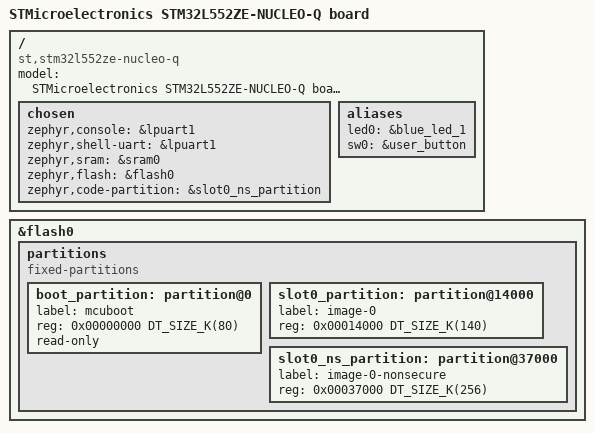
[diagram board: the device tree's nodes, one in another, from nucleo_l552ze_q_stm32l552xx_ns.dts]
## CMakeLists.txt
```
cmake_minimum_required(VERSION 3.20.0)

# Ensure USART2 (VCP) overlay is applied (force cache for sysbuild)
set(DTC_OVERLAY_FILE ${CMAKE_CURRENT_LIST_DIR}/boards/nucleo_l552ze_q.overlay CACHE STRING "" FORCE)

find_package(Zephyr REQUIRED HINTS $ENV{ZEPHYR_BASE})

project(tensorflow_hello_world)

# ============================================================
# TF-M CONFIG
# ============================================================
if(TARGET tfm)
  get_target_property(TFM_BINARY_DIR tfm TFM_BINARY_DIR)

  configure_file(
    ${CMAKE_CURRENT_LIST_DIR}/dummy_partition/tfm_manifest_list.yaml.in
    ${CMAKE_CURRENT_BINARY_DIR}/dummy_partition/tfm_manifest_list.yaml
  )

  set_property(TARGET zephyr_property_target
    APPEND PROPERTY TFM_CMAKE_OPTIONS
    -DTFM_EXTRA_MANIFEST_LIST_FILES=${CMAKE_CURRENT_BINARY_DIR}/dummy_partition/tfm_manifest_list.yaml
    -DTFM_EXTRA_PARTITION_PATHS=${CMAKE_CURRENT_LIST_DIR}/dummy_partition
  )
endif()

# ============================================================
# C++ static init fix (important for Cortex-M)
# ============================================================
set(NO_THREADSAFE_STATICS $<TARGET_PROPERTY:compiler-cpp,no_threadsafe_statics>)
zephyr_compile_options($<$<COMPILE_LANGUAGE:CXX>:${NO_THREADSAFE_STATICS}>)

# ============================================================
# Application sources
# ============================================================
target_sources(app PRIVATE
    src/main.cpp
    src/create_enclave.cpp
    src/split_inference.cpp
    src/test_images.c
    src/benchmark.cpp
    src/secure_benchmark_ns.cpp
    src/inference_protocol.cpp
    src/uart_protocol.cpp
    split_inference/late/L_nn_wt_encrypted_data.c
    src/run_enclave.cpp
)

target_link_options(app PRIVATE
    -Wl,--undefined=ns_run_enclave
)

zephyr_linker_sources(SECTIONS ${CMAKE_CURRENT_SOURCE_DIR}/src/model_ro.ld)
#zephyr_linker_sources(SECTIONS linker.ld)

# ============================================================
# Include directories (APP ONLY)
# ============================================================
target_include_directories(app PRIVATE
    ${TFM_BINARY_DIR}/api_ns/interface/include

    # TFLite Micro
    ${ZEPHYR_BASE}/../optional/modules/lib/tflite-micro
    ${ZEPHYR_BASE}/../optional/modules/lib/tflite-micro/tensorflow
    ${ZEPHYR_BASE}/../optional/modules/lib/tflite-micro/tensorflow/lite
    ${ZEPHYR_BASE}/../optional/modules/lib/tflite-micro/tensorflow/lite/micro
    ${ZEPHYR_BASE}/../optional/modules/lib/tflite-micro/tensorflow/lite/kernels

    # SecureQNN / generated headers
    ${CMAKE_CURRENT_LIST_DIR}/src
    #${CMAKE_CURRENT_LIST_DIR}/src/ns
    #${CMAKE_CURRENT_LIST_DIR}/src/s
)

# ============================================================
# CMSIS-NN (Zephyr library)
# ============================================================
add_subdirectory(src/CMSIS_NN)

# ============================================================
# Compile definitions
# ============================================================
target_compile_definitions(app PRIVATE
    TFM_PARTITION_DUMMY_PARTITION
    
)

# ================= CMSIS-NN =================
set(CMSIS_NN_PATH ${CMAKE_CURRENT_SOURCE_DIR}/src/CMSIS_NN)

zephyr_include_directories(
    ${CMSIS_NN_PATH}/Include
)

file(GLOB_RECURSE CMSIS_NN_SOURCES
    ${CMSIS_NN_PATH}/Source/*.c
)

target_sources(app PRIVATE ${CMSIS_NN_SOURCES})
```

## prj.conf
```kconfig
# Copyright 2019 The TensorFlow Authors. All Rights Reserved.
#
# Licensed under the Apache License, Version 2.0 (the "License");
# you may not use this file except in compliance with the License.
# You may obtain a copy of the License at
#
#    http://www.apache.org/licenses/LICENSE-2.0
#
# Unless required by applicable law or agreed to in writing, software
# distributed under the License is distributed on an "AS IS" BASIS,
# WITHOUT WARRANTIES OR CONDITIONS OF ANY KIND, either express or implied.
# See the License for the specific language governing permissions and
# limitations under the License.
# ==============================================================================s
CONFIG_CPP=y
CONFIG_STD_CPP17=y
CONFIG_TENSORFLOW_LITE_MICRO=y
CONFIG_MAIN_STACK_SIZE=3072
CONFIG_REQUIRES_FLOAT_PRINTF=n
#CONFIG_HEAP_MEM_POOL_SIZE=65536

CONFIG_BUILD_WITH_TFM=y
CONFIG_TFM_PROFILE_TYPE_NOT_SET=y
CONFIG_TFM_CONNECTION_BASED_SERVICE_API=y
CONFIG_TFM_PARTITION_CRYPTO=y
CONFIG_TFM_IPC=y
CONFIG_MBEDTLS_PSA_CRYPTO_C=y

# ============================================================
# STM32L5 Hardware Crypto Acceleration
# ============================================================
# HW crypto is controlled by TF-M/platform defaults in this workspace.
# Keep only supported symbols here to avoid Kconfig aborts.
CONFIG_MBEDTLS_DEBUG=y

# CMSIS
CONFIG_CMSIS_NN=y

# Performance monitoring (for benchmarking)
CONFIG_THREAD_RUNTIME_STATS=y
CONFIG_SYS_HEAP_RUNTIME_STATS=y
# CONFIG_SPEED_OPTIMIZATIONS=y  # disabled: caused TF-M build to overflow FLASH


# Silence console/log output to avoid UART protocol interference
CONFIG_LOG=n
CONFIG_PRINTK=n
CONFIG_CONSOLE=n
CONFIG_UART_CONSOLE=n
CONFIG_STDOUT_CONSOLE=n
CONFIG_BOOT_BANNER=n
CONFIG_TFM_LOG_LEVEL_SILENCE=y
CONFIG_TFM_SPM_LOG_LEVEL_SILENCE=y
CONFIG_TFM_PARTITION_LOG_LEVEL_SILENCE=y
CONFIG_TFM_BL2_LOG_LEVEL_OFF=y
CONFIG_TFM_EXCEPTION_INFO_DUMP=n



#CONFIG_TFM_PARTITION_INTERNAL_TRUSTED_STORAGE=n
CONFIG_TFM_PARTITION_INITIAL_ATTESTATION=n
#CONFIG_TFM_PARTITION_PLATFORM=n
CONFIG_TFM_PARTITION_PROTECTED_STORAGE=n
CONFIG_TFM_PARTITION_FIRMWARE_UPDATE=n


#CONFIG_USERSPACE=y
#CONFIG_THREAD_STACK_INFO=y

CONFIG_SERIAL=y
CONFIG_UART_INTERRUPT_DRIVEN=y
CONFIG_GPIO=y
```

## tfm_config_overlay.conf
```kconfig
/* TF-M Crypto acceleration */
TFM_CRYPTO_ASYM_HW_ACCELERATOR=y
TFM_CRYPTO_HW_ACCELERATOR=y
CRYPTO_ENGINE_BACKEND_STM32_PKA=y
```

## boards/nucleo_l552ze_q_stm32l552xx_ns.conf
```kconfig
CONFIG_FLASH_LOAD_OFFSET=0x41000
CONFIG_FLASH_LOAD_SIZE=0x48000
```

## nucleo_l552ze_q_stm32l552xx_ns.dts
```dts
/*
 * Copyright (c) 2020 STMicroelectronics
 *
 * SPDX-License-Identifier: Apache-2.0
 */

/dts-v1/;
#include "nucleo_l552ze_q-common.dtsi"

/ {
	model = "STMicroelectronics STM32L552ZE-NUCLEO-Q board";
	compatible = "st,stm32l552ze-nucleo-q";

	#address-cells = <1>;
	#size-cells = <1>;

	chosen {
		zephyr,console = &lpuart1;
		zephyr,shell-uart = &lpuart1;
		zephyr,sram = &sram0;
		zephyr,flash = &flash0;
		zephyr,code-partition = &slot0_ns_partition;
	};

	aliases {
		led0 = &blue_led_1;
		sw0 = &user_button;
	};
};

&flash0 {

	partitions {
		compatible = "fixed-partitions";
		#address-cells = <1>;
		#size-cells = <1>;

		/*
		 * Following flash partition is compatible with requirements
		 * given in TFM configuration given for current board:
		 * multiple image boot, no tests.
		 * It might require adjustment depending on evolutions on TFM.
		 */

		boot_partition: partition@0 {
			label = "mcuboot";
			reg = <0x00000000 DT_SIZE_K(80)>;
			read-only;
		};
		/* Secure image primary slot */
		slot0_partition: partition@14000 {
			label = "image-0";
			//reg = <0x00014000 DT_SIZE_K(180)>;
			reg = <0x00014000 DT_SIZE_K(140)>; // 0x23000
		};
		/* Non-secure image primary slot */
		//slot0_ns_partition: partition@41000 { //180KB prev
		slot0_ns_partition: partition@37000 {
			label = "image-0-nonsecure";
			reg = <0x00037000 DT_SIZE_K(256)>;
			//reg = <0x00037000 DT_SIZE_K(76)>; // 0x13000
			// reg = <0x00041000 DT_SIZE_K(36)>; // 36864 = 0x9000
		}; 
		/* Secure image secondary slot */
		// slot1_partition: partition@4a000 { // prev
		/*slot1_partition: partition@4a000 {
			label = "image-1";
			//reg = <0x0004a000 DT_SIZE_K(180)>; // 184320 = 0x2d000
			reg = <0x0004a000 DT_SIZE_K(4)>;
			//reg = <0x0004a000 DT_SIZE_K(140)>;
		};*/
		/* Non-secure image secondary slot */
		// slot1_ns_partition: partition@77000 { // prev
		/*slot1_ns_partition: partition@4b000 {
		//slot1_ns_partition: partition@6d000 {
			label = "image-1-nonsecure";
			// reg = <0x00077000 DT_SIZE_K(36)>; // prev
			reg = <0x0004b000 DT_SIZE_K(4)>;
			//reg = <0x0006d000 DT_SIZE_K(76)>;
		};*/
		/* Applicative Non Volatile Storage */
		/* Not available in this config, use secure storage */
	};
};
```

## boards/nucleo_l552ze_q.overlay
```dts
/ {
    chosen {
        zephyr,console = &lpuart1;
        zephyr,shell-uart = &lpuart1;
    };
};
```

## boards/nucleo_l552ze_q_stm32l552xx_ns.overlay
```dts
/ {
    chosen {
        zephyr,console = &usart2;
        zephyr,shell-uart = &usart2;
    };
};

&usart2 {
    status = "okay";
    current-speed = <115200>;
    pinctrl-0 = <&usart2_tx_pa2 &usart2_rx_pa3>;
    pinctrl-names = "default";
};
```

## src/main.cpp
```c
#include <zephyr/kernel.h>
#include <zephyr/sys/printk.h>
#include <zephyr/device.h>
#include <zephyr/drivers/uart.h>
// #include "inference.h"  // Legacy full-model path (not used)
#include "run_enclave.h"
#include "create_enclave.h"
#include "split_inference.h"
#include "benchmark.h"
#include "secure_benchmark_ns.h"
#include "uart_protocol.h"

/* Configuration: Set to 1 for simple UART test, 0 for normal flow */
#define SIMPLE_UART_MODE 0

/* Configuration: Set to 1 for Mac interactive mode, 0 for auto test */
#define MAC_INTERACTIVE_MODE 1


/* Linker symbols pour calculs mémoire */
extern char __bss_start[];
extern char __bss_end[];
extern char __data_start[];
extern char __data_end[];

static void print_memory_stats(void)
{
    size_t bss_size = (size_t)(__bss_end - __bss_start);
    size_t data_size = (size_t)(__data_end - __data_start);

    printk("\n======= NS MEMORY STATS =======\n");
    printk("  BSS size:   %zu bytes\n", bss_size);
    printk("  DATA size:  %zu bytes\n", data_size);
    printk("  Stack ptr:  %p\n", (void*)&bss_size);
    printk("===============================\n\n");
}

/*
 * Override Zephyr's fatal error handler to print a diagnostic message
 * when the SAU isolation test triggers a HardFault (NS->Secure access).
 * After printing, the system halts (or reboots) as usual.
 */
extern "C" void k_sys_fatal_error_handler(unsigned int reason,
                                          const struct arch_esf *esf)
{
    (void)esf;
    printk("\n[SAU TEST] FATAL ERROR: HardFault (reason=%u)\n", reason);
    printk("[SAU TEST] SAU isolation VERIFIED: NS access to Secure enclave ");
    printk("window triggers HardFault as expected.\n");
    printk("[SAU TEST] ========================\n\n");
    k_fatal_halt(reason);
}

int main(void)
{
#if SIMPLE_UART_MODE
    const struct device *uart = DEVICE_DT_GET(DT_NODELABEL(lpuart1));
    if (!device_is_ready(uart)) {
        while (1) {
            k_sleep(K_FOREVER);
        }
    }

    // Simple test: Mac sends 0x01, device responds 0x02
    while (1) {
        uint8_t byte;
        if (uart_poll_in(uart, &byte) == 0) {
            if (byte == 0x01) {
                uart_poll_out(uart, 0x02);
            }
        }
        k_sleep(K_MSEC(1));
    }
#endif

    // All console output disabled to avoid interfering with binary UART protocol
    // (CONFIG_PRINTK=n in prj.conf disables printk at compile time)

    /* Initialize benchmark system */
    benchmark_init();

    // print_memory_stats();

#if MAC_INTERACTIVE_MODE
    /* MAC INTERACTIVE MODE: Device waits for commands from Mac */
    /* All console output disabled to avoid interfering with binary protocol */

    /* Initialize UART protocol */
    while (uart_protocol_init() != 0) {
        k_sleep(K_MSEC(100));
    }

    /* Main loop: process incoming commands - no console output to avoid protocol interference */
    while (1) {
        uart_protocol_process();
        k_yield();
    }

#else
    /* AUTO TEST MODE: Run automated tests */
    printk("\n[MAIN] AUTO MODE\n");
    /* Single inference in enclave */
    printk("\n[MAIN] Running single inference in enclave...\n");
    run_enclave();
    printk("[MAIN] ✓ Inference complete\n\n");

    print_memory_stats();

    /* Update final memory metrics */
    benchmark_get_heap_usage(&g_benchmark_metrics.heap_used_bytes,
                            &g_benchmark_metrics.heap_free_bytes,
                            NULL);
    g_benchmark_metrics.stack_used_bytes = benchmark_get_stack_usage();

    /* Get RAM and Flash usage */
    benchmark_get_memory_usage(&g_benchmark_metrics.ram_used_bytes,
                              &g_benchmark_metrics.ram_total_bytes,
                              &g_benchmark_metrics.flash_used_bytes,
                              &g_benchmark_metrics.flash_total_bytes);

    printk("\n========================================\n");
    printk("=== All operations completed ===\n");
    printk("========================================\n\n");

    /* Print comprehensive benchmark report */
    benchmark_print_report(&g_benchmark_metrics);

    /* Retrieve and print Secure partition benchmark */
    secure_benchmark_metrics_ns_t secure_metrics;
    if (get_secure_benchmark_metrics(&secure_metrics) == 0) {
        print_secure_benchmark_report(&secure_metrics);
    } else {
        printk("[NS] Warning: Failed to retrieve Secure benchmark metrics\n");
    }

    while (1) {
        k_sleep(K_FOREVER);
    }
#endif

    return 0;
}
```

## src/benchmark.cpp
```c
#include "benchmark.h"
#include <zephyr/kernel.h>
#include <zephyr/sys/printk.h>
#include <string.h>

// ============================================================================
// Cycle Counter - Using Zephyr's sys_clock_elapsed() instead of DWT
// (DWT is not accessible from Non-Secure world in TrustZone-M)
// ============================================================================

// System clock (STM32L552 default)
#ifndef CONFIG_SYS_CLOCK_HW_CYCLES_PER_SEC
#define CPU_FREQ_HZ 110000000  // 110 MHz default for STM32L552
#else
#define CPU_FREQ_HZ CONFIG_SYS_CLOCK_HW_CYCLES_PER_SEC
#endif

// Global metrics storage
benchmark_metrics_t g_benchmark_metrics;

// Reference point for cycle counting
static uint32_t benchmark_start_cycles = 0;

static uint32_t safe_avg_u64(uint64_t sum, uint32_t count)
{
    if (count == 0U) {
        return 0U;
    }
    return (uint32_t)(sum / count);
}

// ============================================================================
// Initialization
// ============================================================================

void benchmark_init(void)
{
    // Initialize with current kernel cycle count
    benchmark_start_cycles = k_cycle_get_32();
    
    // Reset metrics
    benchmark_reset_metrics();
    
    printk("[BENCHMARK] Initialized - CPU freq: %u MHz\n", CPU_FREQ_HZ / 1000000);
}

// ============================================================================
// Cycle Counter Implementation
// Using Zephyr's k_cycle_get_32() for TrustZone-M safe access
// ============================================================================

uint32_t benchmark_get_cycles(void)
{
    // Get current cycle count and calculate elapsed
    uint32_t current_cycles = k_cycle_get_32();
    uint32_t elapsed_cycles = current_cycles - benchmark_start_cycles;
    
    return elapsed_cycles;
}

uint32_t benchmark_cycles_to_us(uint32_t cycles)
{
    // Convert cycles to microseconds
    // us = cycles / (freq_hz / 1000000)
    return (uint32_t)((uint64_t)cycles * 1000000ULL / CPU_FREQ_HZ);
}

double benchmark_cycles_to_seconds(uint64_t cycles)
{
    return ((double)cycles) / (double)CPU_FREQ_HZ;
}

uint32_t benchmark_cycles_to_ms(uint32_t cycles)
{
    // Convert cycles to milliseconds
    return (uint32_t)((uint64_t)cycles * 1000ULL / CPU_FREQ_HZ);
}

uint32_t benchmark_measure_ns_stack_zero_time_cycles(uint32_t stack_size_bytes)
{
    const uint32_t target_size = (stack_size_bytes == 0U) ? CONFIG_MAIN_STACK_SIZE : stack_size_bytes;
    volatile uint8_t scratch[CONFIG_MAIN_STACK_SIZE] __attribute__((aligned(8))) = {0};
    const uint32_t bytes_to_zero = (target_size < sizeof(scratch)) ? target_size : (uint32_t)sizeof(scratch);

    /* Prime the buffer so memset cannot be optimized away during analysis. */
    for (size_t i = 0U; i < sizeof(scratch); ++i) {
        scratch[i] = 0xA5U;
    }

    const uint32_t start_cycles = benchmark_get_cycles();
    memset((void *)scratch, 0, bytes_to_zero);
    const uint32_t end_cycles = benchmark_get_cycles();

    volatile uint32_t checksum = 0U;
    for (size_t i = 0U; i < bytes_to_zero; ++i) {
        checksum += scratch[i];
    }
    (void)checksum;

    return end_cycles - start_cycles;
}

// ============================================================================
// Memory Usage Implementation
// ============================================================================

void benchmark_get_heap_usage(uint32_t *used_bytes, uint32_t *free_bytes, uint32_t *total_bytes)
{
    // Simplified implementation - heap runtime stats not always available
    // Return zeros as placeholder (can be enhanced later)
    if (used_bytes) {
        *used_bytes = 0;
    }
    if (free_bytes) {
        *free_bytes = 0;
    }
    if (total_bytes) {
        *total_bytes = 0;
    }
}

uint32_t benchmark_get_stack_usage(void)
{
    // Return approximate stack usage
    // This is a simplified implementation
    return CONFIG_MAIN_STACK_SIZE / 2; // Placeholder estimate
}

void benchmark_get_memory_usage(uint32_t *ram_used, uint32_t *ram_total,
                                uint32_t *flash_used, uint32_t *flash_total)
{
    // Linker symbols for RAM sections
    extern char __data_start[], __data_end[];
    extern char __bss_start[], __bss_end[];
    
    // Linker symbols for Flash sections  
    extern char __rom_region_start[];
    extern char __rom_region_end[];
    
    // Calculate RAM usage (DATA + BSS only - stacks/heap managed separately)
    uint32_t data_size = (uint32_t)((uintptr_t)__data_end - (uintptr_t)__data_start);
    uint32_t bss_size = (uint32_t)((uintptr_t)__bss_end - (uintptr_t)__bss_start);
    
    if (ram_used) {
        // DATA + BSS sections only (from linker map)
        *ram_used = data_size + bss_size;
    }
    
    if (ram_total) {
        // STM32L552 NS RAM: 128 KB
        *ram_total = 128 * 1024;
    }
    
    if (flash_used) {
        // Flash used from linker (text + rodata + data init)
        uint32_t rom_size = (uint32_t)((uintptr_t)__rom_region_end - (uintptr_t)__rom_region_start);
        *flash_used = rom_size;
    }
    
    if (flash_total) {
        // STM32L552 NS Flash: 256 KB
        *flash_total = 256 * 1024;
    }
}

// ============================================================================
// Reporting Implementation
// ============================================================================

void benchmark_print_report(const benchmark_metrics_t *metrics)
{
    printk("\n");
    printk("╔══════════════════════════════════════════════════════════════╗\n");
    printk("║           PERFORMANCE BENCHMARK REPORT                      ║\n");
    printk("╠══════════════════════════════════════════════════════════════╣\n");
    
    // Enclave Lifecycle
    printk("║ ENCLAVE LIFECYCLE                                            ║\n");
    printk("╟──────────────────────────────────────────────────────────────╢\n");
    printk("║ Create:    %10u cycles  (%6u ms)                   ║\n",
           metrics->enclave_create_cycles,
           benchmark_cycles_to_ms(metrics->enclave_create_cycles));
    printk("║ Destroy:   %10u cycles  (%6u ms)                   ║\n",
           metrics->enclave_destroy_cycles,
           benchmark_cycles_to_ms(metrics->enclave_destroy_cycles));
    printk("║ Recreations: %8u times                                 ║\n",
           metrics->enclave_recreations);
    printk("╟──────────────────────────────────────────────────────────────╢\n");
    
    // Cryptographic Operations
    printk("║ CRYPTOGRAPHIC OPERATIONS                                     ║\n");
    printk("╟──────────────────────────────────────────────────────────────╢\n");
    printk("║ AES Decrypt: %8u cycles  (%6u ms)                   ║\n",
           metrics->aes_decrypt_cycles,
           benchmark_cycles_to_ms(metrics->aes_decrypt_cycles));
    printk("╟──────────────────────────────────────────────────────────────╢\n");
    
    // Inference Performance
    printk("║ INFERENCE PERFORMANCE                                        ║\n");
    printk("╟──────────────────────────────────────────────────────────────╢\n");
    printk("║ Early Layers:  %8u cycles  (%6u ms)                 ║\n",
           metrics->early_layers_cycles,
           benchmark_cycles_to_ms(metrics->early_layers_cycles));
    printk("║ Late Layers:   %8u cycles  (%6u ms)                 ║\n",
           metrics->late_layers_cycles,
           benchmark_cycles_to_ms(metrics->late_layers_cycles));
    printk("║ Total Inf:     %8u cycles  (%6u ms)                 ║\n",
           metrics->total_inference_cycles,
           benchmark_cycles_to_ms(metrics->total_inference_cycles));
    printk("╟──────────────────────────────────────────────────────────────╢\n");
    
        // End-to-End
    printk("║ END-TO-END METRICS                                           ║\n");
    printk("╟──────────────────────────────────────────────────────────────╢\n");
        printk("║ run_enclave(last): %8u cycles  (%6u ms)            ║\n",
           metrics->run_enclave_cycles,
           benchmark_cycles_to_ms(metrics->run_enclave_cycles));
    printk("║ Inferences:    %8u total                               ║\n",
           metrics->inference_count);

        if (metrics->full_execute_count > 0U) {
         uint32_t full_execute_avg = safe_avg_u64(metrics->full_execute_sum_cycles,
                                metrics->full_execute_count);
         printk("║ full_execute(last): %8u cycles  (%6u ms)          ║\n",
             metrics->full_execute_cycles,
             benchmark_cycles_to_ms(metrics->full_execute_cycles));
         printk("║ full_execute(avg):  %8u cycles  (%6u ms)          ║\n",
             full_execute_avg,
             benchmark_cycles_to_ms(full_execute_avg));
         printk("║ full_execute(min/max): %5u / %5u ms             ║\n",
             benchmark_cycles_to_ms(metrics->full_execute_min_cycles),
             benchmark_cycles_to_ms(metrics->full_execute_max_cycles));
        }

        if (metrics->run_enclave_count > 0U) {
            uint32_t avg_cycles = safe_avg_u64(metrics->run_enclave_sum_cycles,
                                               metrics->run_enclave_count);
            printk("║ run_enclave(avg):  %8u cycles  (%6u ms)          ║\n",
                   avg_cycles,
                   benchmark_cycles_to_ms(avg_cycles));
            printk("║ run_enclave(min/max): %6u / %6u ms               ║\n",
                   benchmark_cycles_to_ms(metrics->run_enclave_min_cycles),
                   benchmark_cycles_to_ms(metrics->run_enclave_max_cycles));
            uint32_t avg_ms = benchmark_cycles_to_ms(avg_cycles);
            if (avg_ms > 0U) {
                printk("║ Approx throughput:  %8u inf/s                     ║\n", 1000U / avg_ms);
            }
        }

        if (metrics->irq_atomic_count > 0U) {
            uint32_t irq_avg = safe_avg_u64(metrics->irq_atomic_sum_cycles,
                                            metrics->irq_atomic_count);
            printk("║ IRQ-masked(avg):   %8u cycles  (%6u us)          ║\n",
                   irq_avg,
                   benchmark_cycles_to_us(irq_avg));
            printk("║ IRQ-masked(min/max): %6u / %6u us               ║\n",
                   benchmark_cycles_to_us(metrics->irq_atomic_min_cycles),
                   benchmark_cycles_to_us(metrics->irq_atomic_max_cycles));
        }

         if (metrics->create_atomic_count > 0U) {
             uint32_t create_atomic_avg = safe_avg_u64(metrics->create_atomic_sum_cycles,
                                     metrics->create_atomic_count);
             printk("║ CREATE atomic(avg): %8u cycles  (%6u us)         ║\n",
                 create_atomic_avg,
                 benchmark_cycles_to_us(create_atomic_avg));
             printk("║ CREATE atomic(min/max): %5u / %5u us            ║\n",
                 benchmark_cycles_to_us(metrics->create_atomic_min_cycles),
                 benchmark_cycles_to_us(metrics->create_atomic_max_cycles));
         }

         if (metrics->destroy_atomic_count > 0U) {
             uint32_t destroy_atomic_avg = safe_avg_u64(metrics->destroy_atomic_sum_cycles,
                                      metrics->destroy_atomic_count);
             printk("║ DESTROY atomic(avg): %7u cycles  (%6u us)        ║\n",
                 destroy_atomic_avg,
                 benchmark_cycles_to_us(destroy_atomic_avg));
             printk("║ DESTROY atomic(min/max): %4u / %5u us           ║\n",
                 benchmark_cycles_to_us(metrics->destroy_atomic_min_cycles),
                 benchmark_cycles_to_us(metrics->destroy_atomic_max_cycles));
         }

        printk("║ Requests total: %8u | EnclaveInfo fail: %6u        ║\n",
               metrics->inference_requests_total,
               metrics->enclave_info_validation_failures);

        printk("╟──────────────────────────────────────────────────────────────╢\n");

        // Memory Usage
    printk("║ MEMORY USAGE                                                 ║\n");
    printk("╟──────────────────────────────────────────────────────────────╢\n");
    
    // RAM
    if (metrics->ram_total_bytes > 0) {
        uint32_t ram_pct = (metrics->ram_used_bytes * 100) / metrics->ram_total_bytes;
        printk("║ RAM Used:   %10u / %6u bytes  (%3u%%)            ║\n",
               metrics->ram_used_bytes, metrics->ram_total_bytes, ram_pct);
        printk("║             %10u / %6u KB                        ║\n",
               metrics->ram_used_bytes / 1024, metrics->ram_total_bytes / 1024);
    }
    
    // Flash
    if (metrics->flash_total_bytes > 0) {
        uint32_t flash_pct = (metrics->flash_used_bytes * 100) / metrics->flash_total_bytes;
        printk("║ Flash Used: %10u / %6u bytes  (%3u%%)            ║\n",
               metrics->flash_used_bytes, metrics->flash_total_bytes, flash_pct);
        printk("║             %10u / %6u KB                        ║\n",
               metrics->flash_used_bytes / 1024, metrics->flash_total_bytes / 1024);
    }
    
    printk("╟──────────────────────────────────────────────────────────────╢\n");
    printk("║ Heap Used:  %10u bytes  (%6u KB)                  ║\n",
           metrics->heap_used_bytes, metrics->heap_used_bytes / 1024);
    printk("║ Heap Free:  %10u bytes  (%6u KB)                  ║\n",
           metrics->heap_free_bytes, metrics->heap_free_bytes / 1024);
    printk("║ Stack Used: %10u bytes  (%6u KB)                  ║\n",
           metrics->stack_used_bytes, metrics->stack_used_bytes / 1024);
    printk("╚══════════════════════════════════════════════════════════════╝\n");
    printk("\n");

        printk("[BENCHMARK][CSV] stage,count,sum_cycles,avg_cycles,min_cycles,max_cycles\n");
        printk("[BENCHMARK][CSV] enclave_create,%u,%llu,%u,%u,%u\n",
            metrics->enclave_create_count,
            (unsigned long long)metrics->enclave_create_sum_cycles,
            safe_avg_u64(metrics->enclave_create_sum_cycles, metrics->enclave_create_count),
            metrics->enclave_create_min_cycles,
            metrics->enclave_create_max_cycles);
        printk("[BENCHMARK][CSV] enclave_destroy,%u,%llu,%u,%u,%u\n",
            metrics->enclave_destroy_count,
            (unsigned long long)metrics->enclave_destroy_sum_cycles,
            safe_avg_u64(metrics->enclave_destroy_sum_cycles, metrics->enclave_destroy_count),
            metrics->enclave_destroy_min_cycles,
            metrics->enclave_destroy_max_cycles);
        printk("[BENCHMARK][CSV] aes_decrypt,%u,%llu,%u,%u,%u\n",
            metrics->aes_decrypt_count,
            (unsigned long long)metrics->aes_decrypt_sum_cycles,
            safe_avg_u64(metrics->aes_decrypt_sum_cycles, metrics->aes_decrypt_count),
            metrics->aes_decrypt_min_cycles,
            metrics->aes_decrypt_max_cycles);
        printk("[BENCHMARK][CSV] early_layers,%u,%llu,%u,%u,%u\n",
            metrics->early_layers_count,
            (unsigned long long)metrics->early_layers_sum_cycles,
            safe_avg_u64(metrics->early_layers_sum_cycles, metrics->early_layers_count),
            metrics->early_layers_min_cycles,
            metrics->early_layers_max_cycles);
        printk("[BENCHMARK][CSV] late_layers,%u,%llu,%u,%u,%u\n",
            metrics->late_layers_count,
            (unsigned long long)metrics->late_layers_sum_cycles,
            safe_avg_u64(metrics->late_layers_sum_cycles, metrics->late_layers_count),
            metrics->late_layers_min_cycles,
            metrics->late_layers_max_cycles);
        printk("[BENCHMARK][CSV] total_inference,%u,%llu,%u,%u,%u\n",
            metrics->total_inference_count,
            (unsigned long long)metrics->total_inference_sum_cycles,
            safe_avg_u64(metrics->total_inference_sum_cycles, metrics->total_inference_count),
            metrics->total_inference_min_cycles,
            metrics->total_inference_max_cycles);
        printk("[BENCHMARK][CSV] run_enclave,%u,%llu,%u,%u,%u\n",
            metrics->run_enclave_count,
            (unsigned long long)metrics->run_enclave_sum_cycles,
            safe_avg_u64(metrics->run_enclave_sum_cycles, metrics->run_enclave_count),
            metrics->run_enclave_min_cycles,
            metrics->run_enclave_max_cycles);
        printk("[BENCHMARK][CSV] execute_verified,%u,%llu,%u,%u,%u\n",
            metrics->execute_verified_count,
            (unsigned long long)metrics->execute_verified_sum_cycles,
            safe_avg_u64(metrics->execute_verified_sum_cycles, metrics->execute_verified_count),
            metrics->execute_verified_min_cycles,
            metrics->execute_verified_max_cycles);
        printk("[BENCHMARK][CSV] irq_atomic,%u,%llu,%u,%u,%u\n",
            metrics->irq_atomic_count,
            (unsigned long long)metrics->irq_atomic_sum_cycles,
            safe_avg_u64(metrics->irq_atomic_sum_cycles, metrics->irq_atomic_count),
            metrics->irq_atomic_min_cycles,
            metrics->irq_atomic_max_cycles);
        printk("[BENCHMARK][CSV] create_atomic,%u,%llu,%u,%u,%u\n",
            metrics->create_atomic_count,
            (unsigned long long)metrics->create_atomic_sum_cycles,
            safe_avg_u64(metrics->create_atomic_sum_cycles, metrics->create_atomic_count),
            metrics->create_atomic_min_cycles,
            metrics->create_atomic_max_cycles);
        printk("[BENCHMARK][CSV] destroy_atomic,%u,%llu,%u,%u,%u\n",
            metrics->destroy_atomic_count,
            (unsigned long long)metrics->destroy_atomic_sum_cycles,
            safe_avg_u64(metrics->destroy_atomic_sum_cycles, metrics->destroy_atomic_count),
            metrics->destroy_atomic_min_cycles,
            metrics->destroy_atomic_max_cycles);
}

void benchmark_print_memory_summary(void)
{
    uint32_t used, free, total;
    benchmark_get_heap_usage(&used, &free, &total);
    uint32_t stack = benchmark_get_stack_usage();
    
    printk("[BENCHMARK] Memory: Heap=%u/%u KB (%.1f%%), Stack=%u KB\n",
           used / 1024, total / 1024,
            (total > 0) ? (100.0 * (double)used / (double)total) : 0.0,
           stack / 1024);
}

void benchmark_reset_metrics(void)
{
    memset(&g_benchmark_metrics, 0, sizeof(g_benchmark_metrics));
}
```

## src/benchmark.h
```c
#ifndef BENCHMARK_H
#define BENCHMARK_H

#include <stdint.h>
#include <stdbool.h>

#ifdef __cplusplus
extern "C" {
#endif

// ============================================================================
// Performance Counters Initialization
// ============================================================================

/**
 * @brief Initialize DWT cycle counter for precise timing measurements
 * @note Must be called once at startup before any benchmark calls
 */
void benchmark_init(void);

// ============================================================================
// Cycle Counter API
// ============================================================================

/**
 * @brief Get current CPU cycle count
 * @return Current cycle count (32-bit, wraps around)
 */
uint32_t benchmark_get_cycles(void);

/**
 * @brief Convert cycles to microseconds
 * @param cycles Number of CPU cycles
 * @return Time in microseconds
 */
uint32_t benchmark_cycles_to_us(uint32_t cycles);

/**
 * @brief Convert cycles to seconds as a floating-point value
 * @param cycles Number of CPU cycles
 * @return Time in seconds
 */
double benchmark_cycles_to_seconds(uint64_t cycles);

/**
 * @brief Convert cycles to milliseconds
 * @param cycles Number of CPU cycles
 * @return Time in milliseconds
 */
uint32_t benchmark_cycles_to_ms(uint32_t cycles);

/**
 * @brief Measure the CPU cycles needed to zero a memory region matching the
 *        NS stack size. This benchmark uses the STM cycle counter, not a soft
 *        delay, and must be performed on a scratch buffer to avoid corrupting the
 *        currently running stack.
 * @param stack_size_bytes Size in bytes to zero. 0 means CONFIG_MAIN_STACK_SIZE.
 * @return Number of elapsed CPU cycles for the memset operation.
 */
uint32_t benchmark_measure_ns_stack_zero_time_cycles(uint32_t stack_size_bytes);

// ============================================================================
// Memory Usage API
// ============================================================================

/**
 * @brief Get current heap usage statistics
 * @param used_bytes Output: bytes currently allocated
 * @param free_bytes Output: bytes available
 * @param total_bytes Output: total heap size
 */
void benchmark_get_heap_usage(uint32_t *used_bytes, uint32_t *free_bytes, uint32_t *total_bytes);

/**
 * @brief Get stack usage for current thread
 * @return Stack usage in bytes (approximate)
 */
uint32_t benchmark_get_stack_usage(void);

/**
 * @brief Get RAM and Flash usage from linker symbols
 * @param ram_used Output: RAM used in bytes
 * @param ram_total Output: Total RAM available in bytes
 * @param flash_used Output: Flash used in bytes
 * @param flash_total Output: Total Flash available in bytes
 */
void benchmark_get_memory_usage(uint32_t *ram_used, uint32_t *ram_total,
                                uint32_t *flash_used, uint32_t *flash_total);

// ============================================================================
// Performance Metrics Storage
// ============================================================================

typedef struct {
    // Enclave lifecycle
    uint32_t enclave_create_cycles;
    uint32_t enclave_destroy_cycles;
    
    // Decryption (Secure world)
    uint32_t aes_decrypt_cycles;
    
    // Inference
    uint32_t early_layers_cycles;
    uint32_t late_layers_cycles;
    uint32_t total_inference_cycles;
    
    // End-to-end
    uint32_t run_enclave_cycles;

    // Full verified inference flow (handle_run_inference_common)
    uint32_t full_execute_cycles;
    
    // Memory
    uint32_t heap_used_bytes;
    uint32_t heap_free_bytes;
    uint32_t stack_used_bytes;
    
    // RAM/Flash usage (from linker symbols)
    uint32_t ram_used_bytes;
    uint32_t ram_total_bytes;
    uint32_t flash_used_bytes;
    uint32_t flash_total_bytes;
    
    // Counter metrics
    uint32_t inference_count;
    uint32_t enclave_recreations;

    // Request / security counters
    uint32_t inference_requests_total;
    uint32_t enclave_info_validation_failures;

    // Aggregate cycle stats (for paper reporting)
    uint64_t enclave_create_sum_cycles;
    uint64_t enclave_destroy_sum_cycles;
    uint64_t aes_decrypt_sum_cycles;
    uint64_t early_layers_sum_cycles;
    uint64_t late_layers_sum_cycles;
    uint64_t total_inference_sum_cycles;
    uint64_t run_enclave_sum_cycles;
    uint64_t irq_atomic_sum_cycles;

    uint32_t enclave_create_min_cycles;
    uint32_t enclave_create_max_cycles;
    uint32_t enclave_destroy_min_cycles;
    uint32_t enclave_destroy_max_cycles;
    uint32_t aes_decrypt_min_cycles;
    uint32_t aes_decrypt_max_cycles;
    uint32_t early_layers_min_cycles;
    uint32_t early_layers_max_cycles;
    uint32_t late_layers_min_cycles;
    uint32_t late_layers_max_cycles;
    uint32_t total_inference_min_cycles;
    uint32_t total_inference_max_cycles;
    uint32_t run_enclave_min_cycles;
    uint32_t run_enclave_max_cycles;
    uint32_t irq_atomic_min_cycles;
    uint32_t irq_atomic_max_cycles;

    uint32_t enclave_create_count;
    uint32_t enclave_destroy_count;
    uint32_t aes_decrypt_count;
    uint32_t early_layers_count;
    uint32_t late_layers_count;
    uint32_t total_inference_count;
    uint32_t run_enclave_count;
    uint32_t irq_atomic_count;

    uint32_t full_execute_count;

    uint64_t full_execute_sum_cycles;
    uint32_t full_execute_min_cycles;
    uint32_t full_execute_max_cycles;

    // Dedicated atomic operation stats (UART lifecycle critical sections)
    uint64_t create_atomic_sum_cycles;
    uint64_t destroy_atomic_sum_cycles;
    uint32_t create_atomic_min_cycles;
    uint32_t create_atomic_max_cycles;
    uint32_t destroy_atomic_min_cycles;
    uint32_t destroy_atomic_max_cycles;
    uint32_t create_atomic_count;
    uint32_t destroy_atomic_count;

    // UART flow counters for critical feature coverage
    uint32_t run_inference_with_image_count;
    uint32_t dangerous_inference_no_sau_count;
    uint32_t dangerous_read_ram_count;
    uint32_t dangerous_read_rom_count;

    // Measured time for execute_verified_inference() invoked from UART path
    uint32_t execute_verified_cycles;
    uint64_t execute_verified_sum_cycles;
    uint32_t execute_verified_min_cycles;
    uint32_t execute_verified_max_cycles;
    uint32_t execute_verified_count;

    // NS M_update timing (handle_validate_m_update)
    uint64_t authorize_cycles;
    uint32_t authorize_count;
} benchmark_metrics_t;

extern benchmark_metrics_t g_benchmark_metrics;

// ============================================================================
// Reporting API
// ============================================================================

/**
 * @brief Print comprehensive performance report
 * @param metrics Pointer to metrics structure
 */
void benchmark_print_report(const benchmark_metrics_t *metrics);

/**
 * @brief Print memory usage summary
 */
void benchmark_print_memory_summary(void);

/**
 * @brief Reset all metrics to zero
 */
void benchmark_reset_metrics(void);

// ============================================================================
// Convenience Macros
// ============================================================================

#define BENCHMARK_START(var_name) \
    uint32_t var_name##_start = benchmark_get_cycles()

#define BENCHMARK_END(var_name, target_field) \
    do { \
        uint32_t var_name##_end = benchmark_get_cycles(); \
        uint32_t var_name##_elapsed = var_name##_end - var_name##_start; \
        target_field = var_name##_elapsed; \
    } while(0)

#define BENCHMARK_MEASURE(operation, target_field) \
    do { \
        BENCHMARK_START(bench); \
        operation; \
        BENCHMARK_END(bench, target_field); \
    } while(0)

#define BENCHMARK_ACCUMULATE(sample_cycles, sum_field, min_field, max_field, count_field) \
    do { \
        uint32_t __bench_sample = (sample_cycles); \
        (sum_field) += (uint64_t)__bench_sample; \
        if ((count_field) == 0U || __bench_sample < (min_field)) { \
            (min_field) = __bench_sample; \
        } \
        if ((count_field) == 0U || __bench_sample > (max_field)) { \
            (max_field) = __bench_sample; \
        } \
        (count_field)++; \
    } while(0)

#ifdef __cplusplus
}
#endif

#endif // BENCHMARK_H
```

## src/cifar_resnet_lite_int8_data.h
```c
#ifndef CIFAR_RESNET_LITE_INT8_DATA_H
#define CIFAR_RESNET_LITE_INT8_DATA_H

#ifdef __cplusplus
extern "C" {
#endif

extern const unsigned char cifar_resnet_lite_int8[];
extern const unsigned int cifar_resnet_lite_int8_len;

#ifdef __cplusplus
}
#endif

#endif  // CIFAR_RESNET_LITE_INT8_DATA_H
```

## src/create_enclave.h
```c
#ifndef CREATE_ENCLAVE_H
#define CREATE_ENCLAVE_H

#include <stddef.h>
#include <stdint.h>
#include <stdbool.h>

#ifdef __cplusplus
extern "C" {
#endif

int create_enclave(void);
int create_enclave_with_size(size_t decrypt_size_bytes);
int enter_enclave(void);
int destroy_enclave(void);
int update_rate_limit(uint32_t new_limit);
int32_t get_last_create_secure_status(void);

/* Get enclave memory region (for late weights) */
uint8_t* get_enclave_region(void);
size_t get_enclave_region_size(void);
uint32_t get_max_inferences_per_enclave(void);
bool is_enclave_created(void);
size_t get_model_ro_size(void);
size_t get_inference_code_size(void);

/* SAU enclave RAM isolation: open/close the window from NS side */
int enclave_sau_register_window(const uint8_t *base, uint32_t size);
int enclave_sau_open(void);
int enclave_sau_close(void);
int enclave_sau_model_ro_open(void);
int enclave_sau_model_ro_close(void);

/* Boot-time secure EnclaveInfo bootstrap helpers */
int ensure_model_ro_registered(void);
int ensure_inference_code_registered(void);
int initialize_secure_enclave_info_boot(void);
int validate_enclave_info_before_inference(void);

#ifdef __cplusplus
}
#endif

#endif /* CREATE_ENCLAVE_H */
```

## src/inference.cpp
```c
#include "inference.h"
#include <zephyr/kernel.h>
#include <zephyr/sys/printk.h>

#include "tensorflow/lite/micro/micro_interpreter.h"
#include "tensorflow/lite/micro/micro_mutable_op_resolver.h"
#include "tensorflow/lite/schema/schema_generated.h"

#include "cifar_resnet_lite_int8_data.h"  // New lightweight model
#include "create_enclave.h"  // Pour accéder à enclave_memory
#include "test_images.h"


// Placer tout le code dans une section spéciale pour contrôle MPU
//__attribute__((section(".inference_ro"), aligned(32), used))

/* ================= CONFIG ================= */
#define TENSOR_ARENA_SIZE (56 * 1024)
#define INPUT_H 32
#define INPUT_W 32
#define INPUT_C 3
#define NUM_CLASSES 10

/* ================= GLOBALS (file-local) ================= */
alignas(32) static uint8_t tensor_arena[TENSOR_ARENA_SIZE];
static tflite::MicroInterpreter* interpreter = nullptr;
static TfLiteTensor* input = nullptr;
static TfLiteTensor* output = nullptr;

/* ================= PRIVATE FUNCTIONS ================= */
static void tflm_init(void)
{
    printk("\n--- TFLM INITIALIZATION ---\n");
    printk("[INF] Loading model from RAM enclave...\n");

    /* Access model from RAM enclave (copied during create_enclave) */
    extern uint8_t* get_enclave_memory(void);
    const uint8_t* model_ram = get_enclave_memory();
    
    printk("[INF] Model address (RAM): %p\n", (void*)model_ram);
    printk("[INF] Tensor arena: %u bytes at %p\n", (unsigned)TENSOR_ARENA_SIZE,
            (void*)tensor_arena);
    
    const tflite::Model* model = tflite::GetModel(model_ram);
    printk("[INF] ✓ Model loaded from RAM enclave\n");

    if (model->version() != TFLITE_SCHEMA_VERSION) {
        printk("[INF] \u2717 Schema mismatch (got %d, expected %d)\n",
               model->version(), TFLITE_SCHEMA_VERSION);
        interpreter = nullptr;
        return;
    }
    printk("[INF] \u2713 Schema version OK (%d)\n", TFLITE_SCHEMA_VERSION);

    static tflite::MicroMutableOpResolver<20> resolver;
    resolver.AddConv2D();
    resolver.AddDepthwiseConv2D();
    resolver.AddFullyConnected();
    resolver.AddAveragePool2D();
    resolver.AddMaxPool2D();
    resolver.AddReshape();
    resolver.AddSoftmax();
    resolver.AddAdd();
    resolver.AddMul();
    resolver.AddMean();  // For GlobalAveragePooling2D in lite model
    resolver.AddQuantize();
    resolver.AddDequantize();

    static tflite::MicroInterpreter static_interpreter(
        model,
        resolver,
        tensor_arena,
        TENSOR_ARENA_SIZE
    );

    interpreter = &static_interpreter;

    if (interpreter->AllocateTensors() != kTfLiteOk) {
        printk("[INF] AllocateTensors FAILED\n");
        interpreter = nullptr;
        return;
    }

    input  = interpreter->input(0);
    output = interpreter->output(0);

    printk("[INF] TFLM ready\n");
}

static void load_cifar_image(const uint8_t* img)
{
    int size = INPUT_H * INPUT_W * INPUT_C;

    for (int i = 0; i < size; i++) {
        input->data.int8[i] = (int8_t)((int)img[i] - 128);
    }
}

static int get_prediction(void)
{
    int best = 0;
    int8_t max = output->data.int8[0];

    for (int i = 1; i < NUM_CLASSES; i++) {
        int8_t v = output->data.int8[i];
        if (v > max) {
            max = v;
            best = i;
        }
    }
    return best;
}

/* =========================================================
 *  PUBLIC ENTRY POINT
 * ========================================================= */
extern "C" void run_cifar_inference(void)
{
    printk("\n[INF] ===== INFERENCE START =====\n");
    printk("[INF] user mode = %d\n", k_is_user_context());

    if (!interpreter) {
        printk("[INF] Interpreter not ready, initializing...\n");
        tflm_init();
        if (!interpreter) {
            printk("[INF] Interpreter init failed\n");
            return;
        }
    } else {
        printk("[INF] Interpreter already initialized\n");
    }

    for (int test_id = 0; test_id < 2; test_id++) {
        const uint8_t* img = (test_id == 0) ? img_0 : img_1;
        int expected_label = (test_id == 0) ? label_0 : label_1;

        printk("[INF] Test %d | expected = %d\n", test_id, expected_label);
        load_cifar_image(img);
        
        printk("[INF] Image loaded into input tensor\n");

        TfLiteStatus status = interpreter->Invoke();
        printk("[INF] Invoke returned status = %d\n", status);

        if (status == kTfLiteOk) {
            int pred = get_prediction();
            printk("[INF] Prediction = %d\n", pred);
        } else {
            printk("[INF] Invoke FAILED\n");
        }

        k_sleep(K_MSEC(500));
    }
    /* Zeroize sensitive memory */
    for (int i = 0; i < TENSOR_ARENA_SIZE; i++) {
        tensor_arena[i] = 0;
    }
    printk("[INF] ===== INFERENCE END =====\n\n");
}
```

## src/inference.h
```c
#pragma once

#ifdef __cplusplus
extern "C" {
#endif

void run_cifar_inference(void);

#ifdef __cplusplus
}
#endif
```

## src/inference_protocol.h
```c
#ifndef INFERENCE_PROTOCOL_H
#define INFERENCE_PROTOCOL_H

#include <stdint.h>
#include <string.h>

#ifdef __cplusplus
extern "C" {
#endif

/*=============================================================================
 * Inference Protocol Structures (M_inf / PoX)
 *=============================================================================*/

#define MODEL_ID_SIZE           4       // uint32_t
#define NONCE_SIZE              12      // 12 bytes for nonce
#define ECDSA_SIG_SIZE          64      // ECDSA P-256 signature (r||s)
#define CERT_SIZE               16      // Simplified certificate
#define CIFAR10_OUTPUT_SIZE     1       // Single class (0-9)

/*=============================================================================
 * M_inf: Message from Verifier to Device
 *=============================================================================*/

typedef struct {
    uint8_t nonce[NONCE_SIZE];                          // Random 12 bytes
    uint8_t model_id[MODEL_ID_SIZE];                    // Model identifier
    uint8_t signature[ECDSA_SIG_SIZE];                  // Sign(sk_v, nonce||model_id)
} m_inf_t;

/*=============================================================================
 * PoX: Proof of Execution from Device to Verifier
 *=============================================================================*/

typedef struct {
    uint8_t model_id[MODEL_ID_SIZE];                    // Model identifier
    uint8_t cert[CERT_SIZE];                            // Cert(sk_p, model_id)
    uint8_t nonce[NONCE_SIZE];                          // Echo from M_inf
    uint8_t output;                                     // Inference result (0-9)
    uint8_t signature[ECDSA_SIG_SIZE];                  // Sign(sk_d, above fields)
} proof_of_execution_t;

/*=============================================================================
 * Device-Side Functions (Non-Secure)
 *=============================================================================*/

/**
 * Verify M_inf signature (sk_v is known to device)
 * 
 * @param m_inf: Received M_inf message
 * @param verifier_pk: Verifier's ECDSA P-256 public key (64 bytes)
 * @return 1 if signature valid, 0 otherwise
 */
int verify_m_inf(const m_inf_t *m_inf, const uint8_t verifier_pk[64]);

/**
 * Generate PoX (Proof of Execution)
 * 
 * @param m_inf: Original M_inf (for nonce echo)
 * @param inference_output: CIFAR-10 prediction (0-9)
 * @param device_sk: Device's ECDSA P-256 private key (32 bytes)
 * @param cert: Provider's certificate (16 bytes)
 * @param pox: Output proof of execution structure
 * @return 0 on success, -1 on failure
 */
int generate_proof_of_execution(
    const m_inf_t *m_inf,
    uint8_t inference_output,
    const uint8_t device_sk[32],
    const uint8_t cert[CERT_SIZE],
    proof_of_execution_t *pox
);

/*=============================================================================
 * Provider-Side Functions (Simulation in Non-Secure)
 *=============================================================================*/

/**
 * Generate M_inf (Verifier creates request)
 * The input image is not transmitted; the device uses its own stored test image.
 *
 * @param model_id: Model identifier (4 bytes)
 * @param verifier_sk: Verifier's ECDSA P-256 private key (32 bytes)
 * @param m_inf: Output message
 * @return 0 on success, -1 on failure
 */
int generate_m_inf(
    const uint8_t model_id[MODEL_ID_SIZE],
    const uint8_t verifier_sk[32],
    m_inf_t *m_inf
);

/**
 * Verify PoX (Verifier validates proof)
 * 
 * @param pox: Received proof of execution
 * @param device_pk: Device's ECDSA P-256 public key (64 bytes)
 * @param provider_pk: Provider's ECDSA P-256 public key (64 bytes)
 * @return 1 if all signatures valid, 0 otherwise
 */
int verify_proof_of_execution(
    const proof_of_execution_t *pox,
    const uint8_t device_pk[64],
    const uint8_t provider_pk[64]
);

#ifdef __cplusplus
}
#endif

#endif // INFERENCE_PROTOCOL_H
```
